AUTOSAR XML (schema 00050)
package /ComponentTypes
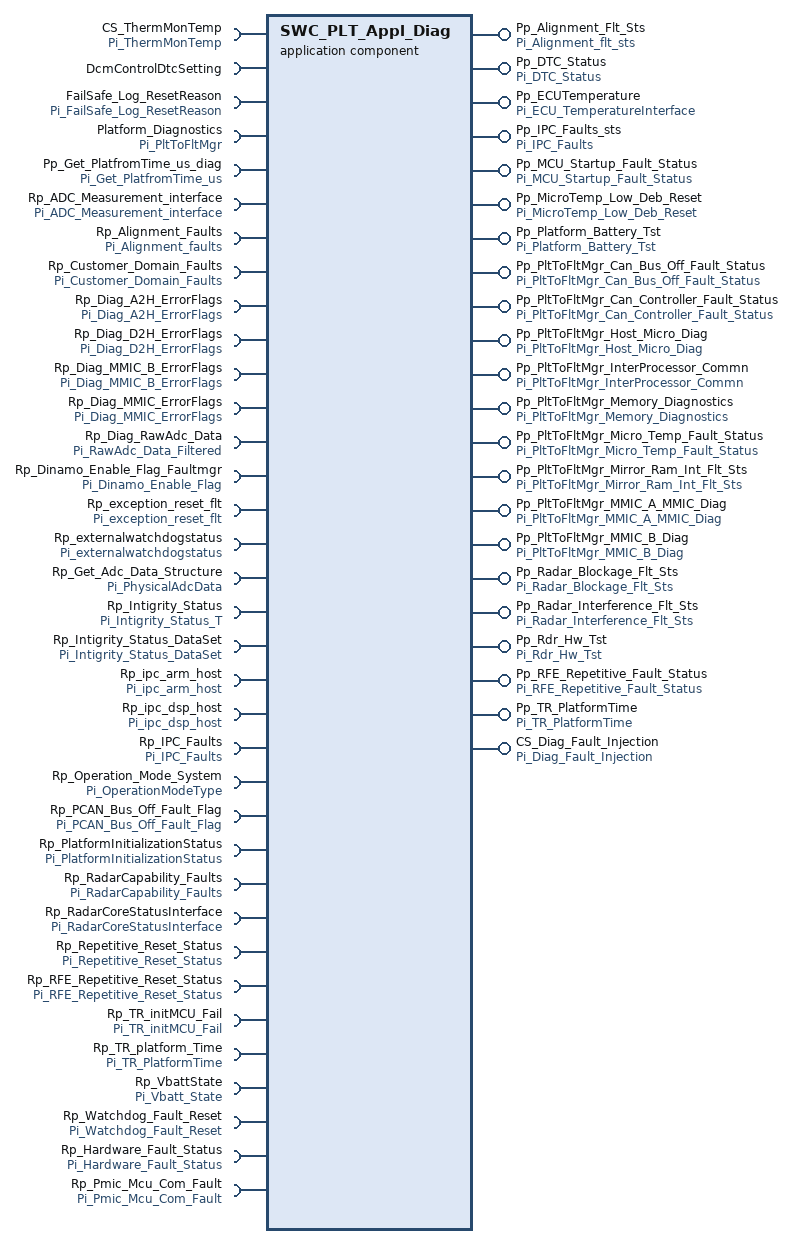
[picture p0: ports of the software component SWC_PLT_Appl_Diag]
  application sw component type SWC_PLT_Appl_Diag  # Implementation of validation diagnostc faults.
    21 x provide port:
      Pp_Alignment_Flt_Sts: nonqueued-sender-com-spec{data-element=De_PltToFltMgr_Alignment_Faults, init-value=constant-reference=C_PltToFltMgr_Alignment_Faults}, provided-interface=Pi_Alignment_flt_sts
      Pp_DTC_Status: nonqueued-sender-com-spec{data-element=De_DTC_Status, init-value=0}, provided-interface=Pi_DTC_Status
      Pp_ECUTemperature: nonqueued-sender-com-spec{data-element=ECUTemperature, init-value=constant-reference=C_ECUTemperature}, provided-interface=Pi_ECU_TemperatureInterface
      Pp_IPC_Faults_sts: nonqueued-sender-com-spec{data-element=De_IPC_Faults, init-value=fields=[IPC_M2D_Crc_Err_Cnt:0, IPC_D2M_Crc_Err_Cnt:0, IPC_D2A_Crc_Err_Cnt:0, IPC_A2M_Crc_Err_Cnt:0]}, provided-interface=Pi_IPC_Faults
      Pp_MCU_Startup_Fault_Status: nonqueued-sender-com-spec{data-element=MCU_Startup_Fault_Status, init-value=fields=[Mcu_Startup_Fault_Status:0, Mcu_Repetitive_Reset_Fault_Status:0]}, provided-interface=Pi_MCU_Startup_Fault_Status
      Pp_MicroTemp_Low_Deb_Reset: nonqueued-sender-com-spec{data-element=De_MicroTemp_Low_Deb_Reset, init-value=85}, provided-interface=Pi_MicroTemp_Low_Deb_Reset
      Pp_Platform_Battery_Tst: nonqueued-sender-com-spec{data-element=De_Platform_Battery_Tst, init-value=constant-reference=C_Battery_Tst_T}, provided-interface=Pi_Platform_Battery_Tst
      Pp_PltToFltMgr_Can_Bus_Off_Fault_Status: nonqueued-sender-com-spec{data-element=De_PltToFltMgr_Can_Bus_Off_Fault_Status, init-value=0}, provided-interface=Pi_PltToFltMgr_Can_Bus_Off_Fault_Status
      Pp_PltToFltMgr_Can_Controller_Fault_Status: nonqueued-sender-com-spec{data-element=De_PltToFltMgr_Can_Controller_Fault_Status, init-value=0}, provided-interface=Pi_PltToFltMgr_Can_Controller_Fault_Status
      Pp_PltToFltMgr_Host_Micro_Diag: nonqueued-sender-com-spec{data-element=De_PltToFltMgr_Host_Micro_Diag, init-value=constant-reference=C_VldtnToFltMgr_Host_Micro_Diag_T}, provided-interface=Pi_PltToFltMgr_Host_Micro_Diag
      Pp_PltToFltMgr_InterProcessor_Commn: nonqueued-sender-com-spec{data-element=De_PltToFltMgr_InterProcessor_Commn_T, init-value=constant-reference=C_VldtnToFltMgr_InterProcessor_Commn_T}, provided-interface=Pi_PltToFltMgr_InterProcessor_Commn
      Pp_PltToFltMgr_Memory_Diagnostics: nonqueued-sender-com-spec{data-element=De_PltToFltMgr_Memory_Diagnostics, init-value=constant-reference=C_VldtnToFltMgr_Memory_Diagnostics_T}, provided-interface=Pi_PltToFltMgr_Memory_Diagnostics
      Pp_PltToFltMgr_Micro_Temp_Fault_Status: nonqueued-sender-com-spec{data-element=De_PltToFltMgr_Micro_Temp_Fault_Status, init-value=constant-reference=C_VldtnToFltMgr_Micro_Temp_Fault_Status_T}, provided-interface=Pi_PltToFltMgr_Micro_Temp_Fault_Status
      Pp_PltToFltMgr_Mirror_Ram_Int_Flt_Sts: nonqueued-sender-com-spec{data-element=PltToFltMgr_Mirror_Ram_Int_Flt_Sts, init-value=0}, provided-interface=Pi_PltToFltMgr_Mirror_Ram_Int_Flt_Sts
      Pp_PltToFltMgr_MMIC_A_MMIC_Diag: nonqueued-sender-com-spec{data-element=De_PltToFltMgr_MMIC_A_MMIC_Diag_T, init-value=constant-reference=C_VldtnToFltMgr_MMIC_A_MMIC_Diag_T}, provided-interface=Pi_PltToFltMgr_MMIC_A_MMIC_Diag
      Pp_PltToFltMgr_MMIC_B_Diag: nonqueued-sender-com-spec{data-element=De_PltToFltMgr_MMIC_B_Diag_T, init-value=constant-reference=C_VldtnToFltMgr_MMIC_B_Diag_T}, provided-interface=Pi_PltToFltMgr_MMIC_B_Diag
      Pp_Radar_Blockage_Flt_Sts: nonqueued-sender-com-spec{data-element=De_Radar_Blockage_Flt_Sts, init-value=constant-reference=C_VldtnToFltMgr_Blockage_Detection_T}, provided-interface=Pi_Radar_Blockage_Flt_Sts
      Pp_Radar_Interference_Flt_Sts: nonqueued-sender-com-spec{data-element=De_Radar_Interference_Flt_Sts, init-value=0}, provided-interface=Pi_Radar_Interference_Flt_Sts
      Pp_Rdr_Hw_Tst: nonqueued-sender-com-spec{data-element=De_Rdr_Hw_Tst, init-value=constant-reference=C_Rdr_Hw_Tst_T}, provided-interface=Pi_Rdr_Hw_Tst
      Pp_RFE_Repetitive_Fault_Status: nonqueued-sender-com-spec{data-element=De_RFE_Repetitive_Fault_Status, init-value=0}, provided-interface=Pi_RFE_Repetitive_Fault_Status
      Pp_TR_PlatformTime: nonqueued-sender-com-spec{data-element=De_PlatformTime, init-value=0}, provided-interface=Pi_TR_PlatformTime
    33 x require port:
      CS_ThermMonTemp: client-com-spec=Read, required-interface=Pi_ThermMonTemp
      DcmControlDtcSetting: mode-switch-receiver-com-spec=DcmControlDtcSetting, required-interface=DcmControlDtcSetting
      FailSafe_Log_ResetReason: client-com-spec=FailSafe_Log_ResetReason, required-interface=Pi_FailSafe_Log_ResetReason
      Platform_Diagnostics: client-com-spec=PltToFltMgr_NvM_FeeCriticalError_Diagnostics, required-interface=Pi_PltToFltMgr
      Pp_Get_PlatfromTime_us_diag: client-com-spec=read, required-interface=Pi_Get_PlatfromTime_us
      Rp_ADC_Measurement_interface: nonqueued-receiver-com-spec{data-element=Element, filter=data-filter-type=ALWAYS, init-value=fields=[TR_MCUtemp_Calflt:0, TR_onboardThermistorFault:0]}, required-interface=Pi_ADC_Measurement_interface
      Rp_Alignment_Faults: nonqueued-receiver-com-spec{data-element=De_Alignment_Faults, filter=data-filter-type=ALWAYS, init-value=constant-reference=C_Alignment_faults}, required-interface=Pi_Alignment_faults
      Rp_Customer_Domain_Faults: nonqueued-receiver-com-spec{data-element=De_Customer_Domain_Faults, filter=data-filter-type=ALWAYS, init-value=constant-reference=C_Customer_Domain_Faults}, required-interface=Pi_Customer_Domain_Faults
      Rp_Diag_A2H_ErrorFlags: nonqueued-receiver-com-spec{data-element=De_A2H_ErrorFlags, filter=data-filter-type=ALWAYS, init-value=constant-reference=C_A2H_ErrorFlags}, required-interface=Pi_Diag_A2H_ErrorFlags
      Rp_Diag_D2H_ErrorFlags: nonqueued-receiver-com-spec{data-element=De_D2H_ErrorFlags, filter=data-filter-type=ALWAYS, init-value=constant-reference=C_D2H_ErrorFlags}, required-interface=Pi_Diag_D2H_ErrorFlags
      Rp_Diag_MMIC_B_ErrorFlags: nonqueued-receiver-com-spec{data-element=De_MMIC_B_ErrorFlags, filter=data-filter-type=ALWAYS, init-value=constant-reference=C_MMIC_B_ErrorFlags}, required-interface=Pi_Diag_MMIC_B_ErrorFlags
      Rp_Diag_MMIC_ErrorFlags: nonqueued-receiver-com-spec{data-element=De_MMIC_ErrorFlags, filter=data-filter-type=ALWAYS, init-value=constant-reference=C_MMIC_ErrorFlags}, required-interface=Pi_Diag_MMIC_ErrorFlags
      Rp_Diag_RawAdc_Data: nonqueued-receiver-com-spec{data-element=De_RawAdcData, filter=data-filter-type=ALWAYS, init-value=constant-reference=C_RawAdcDataFilt_T}, required-interface=Pi_RawAdc_Data_Filtered
      Rp_Dinamo_Enable_Flag_Faultmgr: nonqueued-receiver-com-spec{data-element=De_Dinamo_Enable_Flag, filter=data-filter-type=ALWAYS, init-value=85}, required-interface=Pi_Dinamo_Enable_Flag
      Rp_exception_reset_flt: nonqueued-receiver-com-spec{data-element=exception_reset_flt, filter=data-filter-type=ALWAYS, init-value=0}, required-interface=Pi_exception_reset_flt
      Rp_externalwatchdogstatus: nonqueued-receiver-com-spec{data-element=de_externalwatchdogstatus, filter=data-filter-type=ALWAYS, init-value=0}, required-interface=Pi_externalwatchdogstatus
      Rp_Get_Adc_Data_Structure: nonqueued-receiver-com-spec{data-element=De_PhysicalAdcData, filter=data-filter-type=ALWAYS, init-value=fields=[Adc_Board_Rev:0, Adc_Batt_Volt:0, Adc_Pos_Gnd_A:0, Adc_Pos_Gnd_B:0, Adc_Pos_Gnd_C:0, Adc_Pos_Gnd_D:0, Adc_Eth_0v9:0, Adc_Rdi_Detect:0, Adc_MMIC_Temp:0, Adc_Mcu_Temp:0, Validity_Flag:0]}, required-interface=Pi_PhysicalAdcData
      Rp_Intigrity_Status: nonqueued-receiver-com-spec{data-element=Dt_Intigrity_Status_T, filter=data-filter-type=ALWAYS, init-value=0}, required-interface=Pi_Intigrity_Status_T
      Rp_Intigrity_Status_DataSet: nonqueued-receiver-com-spec{data-element=Intigrity_Status_DataSet, filter=data-filter-type=ALWAYS, init-value=0}, required-interface=Pi_Intigrity_Status_DataSet
      Rp_ipc_arm_host: nonqueued-receiver-com-spec{data-element=ipc_arm_host, filter=data-filter-type=ALWAYS, init-value=0}, required-interface=Pi_ipc_arm_host
      Rp_ipc_dsp_host: nonqueued-receiver-com-spec{data-element=ipc_dsp_host, filter=data-filter-type=ALWAYS, init-value=0}, required-interface=Pi_ipc_dsp_host
      Rp_IPC_Faults: nonqueued-receiver-com-spec{data-element=De_IPC_Faults, filter=data-filter-type=ALWAYS, init-value=fields=[IPC_M2D_Crc_Err_Cnt:0, IPC_D2M_Crc_Err_Cnt:0, IPC_D2A_Crc_Err_Cnt:0, IPC_A2M_Crc_Err_Cnt:0]}, required-interface=Pi_IPC_Faults
      Rp_Operation_Mode_System: nonqueued-receiver-com-spec{data-element=De_OperationMode_System, filter=data-filter-type=ALWAYS, init-value=0}, required-interface=Pi_OperationModeType
      Rp_PCAN_Bus_Off_Fault_Flag: nonqueued-receiver-com-spec{data-element=De_PCAN_Busoff_Fault_Flag, filter=data-filter-type=ALWAYS, init-value=0}, required-interface=Pi_PCAN_Bus_Off_Fault_Flag
      Rp_PlatformInitializationStatus: nonqueued-receiver-com-spec{data-element=De_MCU_InitializationStatus, filter=data-filter-type=ALWAYS, init-value=constant-reference=C_MCU_initlaisation_NOTCompleted_T}, required-interface=Pi_PlatformInitializationStatus
      Rp_RadarCapability_Faults: nonqueued-receiver-com-spec{data-element=De_RadarCapability_Faults, filter=data-filter-type=ALWAYS, init-value=constant-reference=C_RadarCapability}, required-interface=Pi_RadarCapability_Faults
      Rp_RadarCoreStatusInterface: nonqueued-receiver-com-spec{data-element=De_RadarCoreStatus, filter=data-filter-type=ALWAYS, init-value=constant-reference=C_RadarCoreStatus_T}, required-interface=Pi_RadarCoreStatusInterface
      Rp_Repetitive_Reset_Status: nonqueued-receiver-com-spec{data-element=De_Repetitive_Reset_Status, filter=data-filter-type=ALWAYS, init-value=85}, required-interface=Pi_Repetitive_Reset_Status
      Rp_RFE_Repetitive_Reset_Status: nonqueued-receiver-com-spec{data-element=De_RFE_Repetitive_Reset_Status, filter=data-filter-type=ALWAYS, init-value=0}, required-interface=Pi_RFE_Repetitive_Reset_Status
      Rp_TR_initMCU_Fail: nonqueued-receiver-com-spec{data-element=De_TR_InitMCU_fail, filter=data-filter-type=ALWAYS, init-value=constant-reference=CODED_FALSE}, required-interface=Pi_TR_initMCU_Fail
      Rp_TR_platform_Time: nonqueued-receiver-com-spec{data-element=De_PlatformTime, filter=data-filter-type=ALWAYS, init-value=85}, required-interface=Pi_TR_PlatformTime
      Rp_VbattState: nonqueued-receiver-com-spec{data-element=De_Vbatt_State, filter=data-filter-type=ALWAYS, init-value=0}, required-interface=Pi_Vbatt_State
      Rp_Watchdog_Fault_Reset: nonqueued-receiver-com-spec{data-element=De_Watchdog_Fault_Reset, filter=data-filter-type=ALWAYS, init-value=0}, required-interface=Pi_Watchdog_Fault_Reset
    provide port CS_Diag_Fault_Injection: server-com-spec{operation=Read, queue-length=1}, provided-interface=Pi_Diag_Fault_Injection
    require port Rp_Hardware_Fault_Status: nonqueued-receiver-com-spec{data-element=De_Hardware_Fault_Status, filter=data-filter-type=ALWAYS, init-value=fields=RA_Fault_Status:0}, required-interface=Pi_Hardware_Fault_Status
    require port Rp_Pmic_Mcu_Com_Fault: nonqueued-receiver-com-spec{data-element=De_Pmic_Mcu_Com_Fault, filter=data-filter-type=ALWAYS, init-value=0}, required-interface=Pi_Pmic_Mcu_Com_Fault
    behavior SWC_PLT_Appl_Diag_InternalBehavior: handle-termination-and-restart=NO-SUPPORT
      exclusive area ExclusiveArea
      4 x timing event, all with period=0.05:
        TMT_RE_PLT_Diag_Alignment_Diagnostics_50ms: start-on-event=RE_PLT_Diag_Alignment_Diagnostics_50ms
        TMT_RE_Validation_Battery_Fault_Tests: start-on-event=RE_PLT_Diag_Battery_Fault_Tests_50ms
        TMT_RE_Platform_Can_Bus_Off_Fault_Test: start-on-event=RE_PLT_Diag_Can_Bus_Off_Fault_Test_50ms
        TMT_RE_Validation_Host_Microcontroller_Tests: start-on-event=RE_PLT_Diag_Host_Microcontroller_Tests_50ms
      init event SWC_PLT_Appl_Diag_InitEvent: start-on-event=RE_PLT_Diag_Init
      7 x timing event, all with period=0.05:
        TMT_RE_Validation_Inter_Processor_Communication_Diagnostics: start-on-event=RE_PLT_Diag_Inter_Processor_Communication_Diagnostics_50ms
        TMT_RE_Validation_Memory_Diagnostics: start-on-event=RE_PLT_Diag_Memory_Diagnostics_50ms
        TMT_RE_Validation_Microprocessor_Temp_Tests: start-on-event=RE_PLT_Diag_Microprocessor_Temp_Tests_50ms
        TMT_RE_PLT_Diag_PlatformTime_Diagnostics_50ms: start-on-event=RE_PLT_Diag_PlatformTime_50ms
        TMT_RE_Validation_Radar_Blockage_Detection_Test: start-on-event=RE_PLT_Diag_Radar_Blockage_Detection_Test_50ms
        TMT_RE_Validation_Radar_Hardware_Tests: start-on-event=RE_PLT_Diag_Radar_Hardware_Tests_50ms
        TMT_RE_Validation_Dolphin_Chip_Diagnostics: start-on-event=RE_PLT_Diag_Radar_Transceiver_Diagnostics_50ms
      operation invoked event OIT_CS_Diag_Fault_Injection_Read_CS_Diag_Fault_Injection_Read: start-on-event=CS_Diag_Fault_Injection_Read, operation=CS_Diag_Fault_Injection.Read
      13 x runnable:
        RE_PLT_Diag_Alignment_Diagnostics_50ms: mode-access-point=DcmControlDtcSetting.DcmControlDtcSetting
          data-receive-point-by-arguments:
            access REC_Rp_Alignment_faults_De_Alignment_Faults: accessed-variable=Rp_Alignment_Faults.De_Alignment_Faults
          data-send-points:
            access SEND_Pp_Alignment_flt_sts_De_PltToFltMgr_Alignment_Faults: accessed-variable=Pp_Alignment_Flt_Sts.De_PltToFltMgr_Alignment_Faults
        RE_PLT_Diag_Battery_Fault_Tests_50ms
          data-receive-point-by-arguments:
            access REC_Rp_Vbatt_State_De_Vbatt_State: accessed-variable=Rp_VbattState.De_Vbatt_State
          data-send-points:
            access SEND_Pp_Validation_Battery_Tst_De_Validation_Battery_Tst: accessed-variable=Pp_Platform_Battery_Tst.De_Platform_Battery_Tst
        RE_PLT_Diag_Can_Bus_Off_Fault_Test_50ms
          data-receive-point-by-arguments:
            access REC_Rp_PCAN_Bus_Off_Fault_Flag_De_PCAN_Busoff_Fault_Flag: accessed-variable=Rp_PCAN_Bus_Off_Fault_Flag.De_PCAN_Busoff_Fault_Flag
          data-send-points:
            access SEND_Pp_PltToFltMgr_Can_Bus_Off_Fault_Status_De_PltToFltMgr_Can_Bus_Off_Fault_Status: accessed-variable=Pp_PltToFltMgr_Can_Bus_Off_Fault_Status.De_PltToFltMgr_Can_Bus_Off_Fault_Status
        RE_PLT_Diag_Host_Microcontroller_Tests_50ms
          data-receive-point-by-arguments:
            access REC_Rp_externalwatchdogstatus_de_externalwatchdogstatus: accessed-variable=Rp_externalwatchdogstatus.de_externalwatchdogstatus
            access REC_Rp_Repetitive_Reset_Status_De_Repetitive_Reset_Status: accessed-variable=Rp_Repetitive_Reset_Status.De_Repetitive_Reset_Status
            access REC_Rp_Watchdog_Fault_Reset_De_Watchdog_Fault_Reset: accessed-variable=Rp_Watchdog_Fault_Reset.De_Watchdog_Fault_Reset
          data-send-points:
            access SEND_Pp_VldtnToFltMgr_Host_Micro_Diag_De_VldtnToFltMgr_Host_Micro_Diag: accessed-variable=Pp_PltToFltMgr_Host_Micro_Diag.De_PltToFltMgr_Host_Micro_Diag
        RE_PLT_Diag_Init  # Init runnable for the module validation diagnostics.
          data-receive-point-by-arguments:
            access REC_Rp_Repetitive_Reset_Status_De_Repetitive_Reset_Status: accessed-variable=Rp_Repetitive_Reset_Status.De_Repetitive_Reset_Status
            access REC_Rp_RFE_Repetitive_Reset_Status_De_RFE_Repetitive_Reset_Status: accessed-variable=Rp_RFE_Repetitive_Reset_Status.De_RFE_Repetitive_Reset_Status
            access REC_Rp_TR_initMCU_Fail_De_TR_InitMCU_fail: accessed-variable=Rp_TR_initMCU_Fail.De_TR_InitMCU_fail
          data-send-points:
            access SEND_Pp_MCU_Startup_Fault_Status_MCU_Startup_Fault_Status: accessed-variable=Pp_MCU_Startup_Fault_Status.MCU_Startup_Fault_Status
            access SEND_Pp_RFE_Repetitive_Fault_Status_De_RFE_Repetitive_Fault_Status: accessed-variable=Pp_RFE_Repetitive_Fault_Status.De_RFE_Repetitive_Fault_Status
            access SEND_Pp_VldtnToFltMgr_Can_Controller_Fault_Status_De_VldtnToFltMgr_Can_Controller_Fault_Status: accessed-variable=Pp_PltToFltMgr_Can_Controller_Fault_Status.De_PltToFltMgr_Can_Controller_Fault_Status
        RE_PLT_Diag_Inter_Processor_Communication_Diagnostics_50ms  # Runnable for inter process communication diagnostic tests.
          data-receive-point-by-arguments:
            access REC_Rp_ipc_arm_host_ipc_arm_host: accessed-variable=Rp_ipc_arm_host.ipc_arm_host
            access REC_Rp_ipc_dsp_host_ipc_dsp_host: accessed-variable=Rp_ipc_dsp_host.ipc_dsp_host
            access REC_Rp_IPC_Faults_De_IPC_Faults: accessed-variable=Rp_IPC_Faults.De_IPC_Faults
          data-send-points:
            access SEND_Pp_IPC_Faults_sts_De_IPC_Faults: accessed-variable=Pp_IPC_Faults_sts.De_IPC_Faults
            access SEND_Pp_VldtnToFltMgr_InterProcessor_Commn_De_VldtnToFltMgr_InterProcessor_Commn_50ms_T: accessed-variable=Pp_PltToFltMgr_InterProcessor_Commn.De_PltToFltMgr_InterProcessor_Commn_T
        RE_PLT_Diag_Memory_Diagnostics_50ms: runs-inside-exclusive-area=ExclusiveArea  # Runnable for memory diagnostic faults.
          data-receive-point-by-arguments:
            6 x access:
              REC_Rp_Customer_Domain_Faults_De_Customer_Domain_Faults: accessed-variable=Rp_Customer_Domain_Faults.De_Customer_Domain_Faults
              REC_Rp_Diag_A2H_ErrorFlags_De_A2H_ErrorFlags: accessed-variable=Rp_Diag_A2H_ErrorFlags.De_A2H_ErrorFlags
              REC_Rp_Diag_D2H_ErrorFlags_De_D2H_ErrorFlags: accessed-variable=Rp_Diag_D2H_ErrorFlags.De_D2H_ErrorFlags
              REC_Rp_exception_reset_flt_exception_reset_flt: accessed-variable=Rp_exception_reset_flt.exception_reset_flt
              REC_Rp_Intigrity_Status_DataSet_Intigrity_Status_DataSet: accessed-variable=Rp_Intigrity_Status_DataSet.Intigrity_Status_DataSet
              REC_Rp_Intigrity_Status_Dt_Intigrity_Status_T: accessed-variable=Rp_Intigrity_Status.Dt_Intigrity_Status_T
          data-send-points:
            access SEND_Pp_DTC_Status_De_DTC_Status: accessed-variable=Pp_DTC_Status.De_DTC_Status
            access SEND_Pp_PltToFltMgr_Mirror_Ram_Int_Flt_Sts_PltToFltMgr_Mirror_Ram_Int_Flt_Sts: accessed-variable=Pp_PltToFltMgr_Mirror_Ram_Int_Flt_Sts.PltToFltMgr_Mirror_Ram_Int_Flt_Sts
            access SEND_Pp_VldtnToFltMgr_Memory_Diagnostics_De_VldtnToFltMgr_Memory_Diagnostics: accessed-variable=Pp_PltToFltMgr_Memory_Diagnostics.De_PltToFltMgr_Memory_Diagnostics
          sync call SC_FailSafe_Log_ResetReason: operation=FailSafe_Log_ResetReason.FailSafe_Log_ResetReason
          sync call SC_VldnToFltMgr_NvM_FeeCriticalError_Diagnostics_VldnToFltMgr_NvM_FeeCriticalError_Diagnostics: operation=Platform_Diagnostics.PltToFltMgr_NvM_FeeCriticalError_Diagnostics
        RE_PLT_Diag_Microprocessor_Temp_Tests_50ms
          data-receive-point-by-arguments:
            access REC_Rp_ADC_Measurement_interface_Element: accessed-variable=Rp_ADC_Measurement_interface.Element
            access REC_Rp_Diag_RawAdc_Data_De_RawAdcData: accessed-variable=Rp_Diag_RawAdc_Data.De_RawAdcData
            access REC_Rp_Get_Adc_Data_Structure_De_PhysicalAdcData: accessed-variable=Rp_Get_Adc_Data_Structure.De_PhysicalAdcData
          data-send-points:
            access SEND_Pp_ECUTemperature_ECUTemperature: accessed-variable=Pp_ECUTemperature.ECUTemperature
            access SEND_Pp_MicroTemp_Low_Deb_Reset_De_MicroTemp_Low_Deb_Reset: accessed-variable=Pp_MicroTemp_Low_Deb_Reset.De_MicroTemp_Low_Deb_Reset
            access SEND_Pp_VldtnToFltMgr_Micro_Temp_Fault_Status_De_VldtnToFltMgr_Micro_Temp_Fault_Status: accessed-variable=Pp_PltToFltMgr_Micro_Temp_Fault_Status.De_PltToFltMgr_Micro_Temp_Fault_Status
          sync call SC_CS_ThermMonTemp_Read: operation=CS_ThermMonTemp.Read
        RE_PLT_Diag_PlatformTime_50ms
          data-send-points:
            access SEND_Pp_TR_PlatformTime_De_TR_PlatformTime: accessed-variable=Pp_TR_PlatformTime.De_PlatformTime
        RE_PLT_Diag_Radar_Blockage_Detection_Test_50ms
          data-receive-point-by-arguments:
            access REC_Rp_Diag_A2H_ErrorFlags_De_A2H_ErrorFlags: accessed-variable=Rp_Diag_A2H_ErrorFlags.De_A2H_ErrorFlags
            access REC_Rp_Dinamo_Enable_Flag_Faultmgr_De_Dinamo_Enable_Flag: accessed-variable=Rp_Dinamo_Enable_Flag_Faultmgr.De_Dinamo_Enable_Flag
            access REC_Rp_RadarCapability_Faults_De_RadarCapability_Faults: accessed-variable=Rp_RadarCapability_Faults.De_RadarCapability_Faults
          data-send-points:
            access SEND_Pp_Radar_Blockage_Flt_Sts_De_Radar_Blockage_Flt_Sts: accessed-variable=Pp_Radar_Blockage_Flt_Sts.De_Radar_Blockage_Flt_Sts
            access SEND_Pp_Radar_Interference_Flt_Sts_De_Radar_Interference_Flt_Sts: accessed-variable=Pp_Radar_Interference_Flt_Sts.De_Radar_Interference_Flt_Sts
        RE_PLT_Diag_Radar_Hardware_Tests_50ms
          data-receive-point-by-arguments:
            4 x access:
              REC_Rp_OperationMode_System_De_OperationMode_System: accessed-variable=Rp_Operation_Mode_System.De_OperationMode_System
              REC_Rp_TR_PlatformTime_De_TR_PlatformTime: accessed-variable=Rp_TR_platform_Time.De_PlatformTime
              REC_Rp_Hardware_Fault_Status_De_Hardware_Fault_Status: accessed-variable=Rp_Hardware_Fault_Status.De_Hardware_Fault_Status
              REC_Rp_Pmic_Mcu_Com_Fault_De_Pmic_Mcu_Com_Fault: accessed-variable=Rp_Pmic_Mcu_Com_Fault.De_Pmic_Mcu_Com_Fault
          data-send-points:
            access SEND_Pp_Rdr_Hw_Tst_De_Rdr_Hw_Tst: accessed-variable=Pp_Rdr_Hw_Tst.De_Rdr_Hw_Tst
          sync call SC_Pp_Get_PlatfromTime_us_read: operation=Pp_Get_PlatfromTime_us_diag.read
        RE_PLT_Diag_Radar_Transceiver_Diagnostics_50ms
          data-receive-point-by-arguments:
            access REC_Rp_Diag_MMIC_B_ErrorFlags_De_MMIC_B_ErrorFlags: accessed-variable=Rp_Diag_MMIC_B_ErrorFlags.De_MMIC_B_ErrorFlags
            access REC_Rp_Diag_MMIC_ErrorFlags_De_MMIC_ErrorFlags: accessed-variable=Rp_Diag_MMIC_ErrorFlags.De_MMIC_ErrorFlags
            access REC_Rp_RadarCoreStatusInterface_De_RadarCoreStatus: accessed-variable=Rp_RadarCoreStatusInterface.De_RadarCoreStatus
          data-send-points:
            access SEND_Pp_PltToFltMgr_MMIC_B_Diag_De_PltToFltMgr_MMIC_B_Diag_T: accessed-variable=Pp_PltToFltMgr_MMIC_B_Diag.De_PltToFltMgr_MMIC_B_Diag_T
            access SEND_Pp_VldtnToFltMgr_Dolphin_Diag_De_VldtnToFltMgr_Dolphin_Diag: accessed-variable=Pp_PltToFltMgr_MMIC_A_MMIC_Diag.De_PltToFltMgr_MMIC_A_MMIC_Diag_T
        CS_Diag_Fault_Injection_Read
  swc implementation SWC_PLT_Appl_Diag_Implementation: behavior=SWC_PLT_Appl_Diag_InternalBehavior
    code-descriptors:
      code Default: artifact-descriptors=autosar-engineering-object=category=SWSRC
